AUTOSAR XML (schema 4-2-2)
package /CDD_CORE1
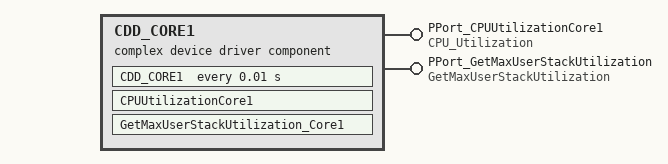
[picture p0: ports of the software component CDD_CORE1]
  complex device driver sw component type CDD_CORE1
    provide port PPort_CPUUtilizationCore1: provided-interface=CPU_Utilization
    provide port PPort_GetMaxUserStackUtilization: provided-interface=GetMaxUserStackUtilization
    behavior SwcInternalBehavior
      operation invoked event OperationInvokedEvent_0: start-on-event=CPUUtilizationCore1, operation=PPort_CPUUtilizationCore1.CPU_Utilization
      timing event TimingEvent_0: start-on-event=CDD_CORE1, period=0.01
      operation invoked event OperationInvokedEvent_1: start-on-event=GetMaxUserStackUtilization_Core1, operation=PPort_GetMaxUserStackUtilization.GetMaxUserStackUtilization
      runnable CPUUtilizationCore1: symbol=CPUUtilizationCore1_func
      runnable CDD_CORE1: symbol=CDD_CORE1_func
      runnable GetMaxUserStackUtilization_Core1: symbol=GetMaxUserStackUtilization_Core1_func
